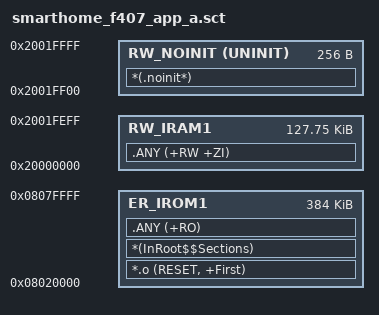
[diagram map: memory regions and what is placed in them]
LR_IROM1 0x08020000 0x00060000  {    ; load region size_region
  ER_IROM1 0x08020000 0x00060000  {  ; load address = execution address
    *.o (RESET, +First)
    *(InRoot$$Sections)
    .ANY (+RO)
  }
  RW_IRAM1 0x20000000 0x0001FF00  {  ; RW/ZI data
    .ANY (+RW +ZI)
  }
  RW_NOINIT 0x2001FF00 UNINIT 0x00000100 { ; retained across reset
    *(.noinit*)
  }
}
